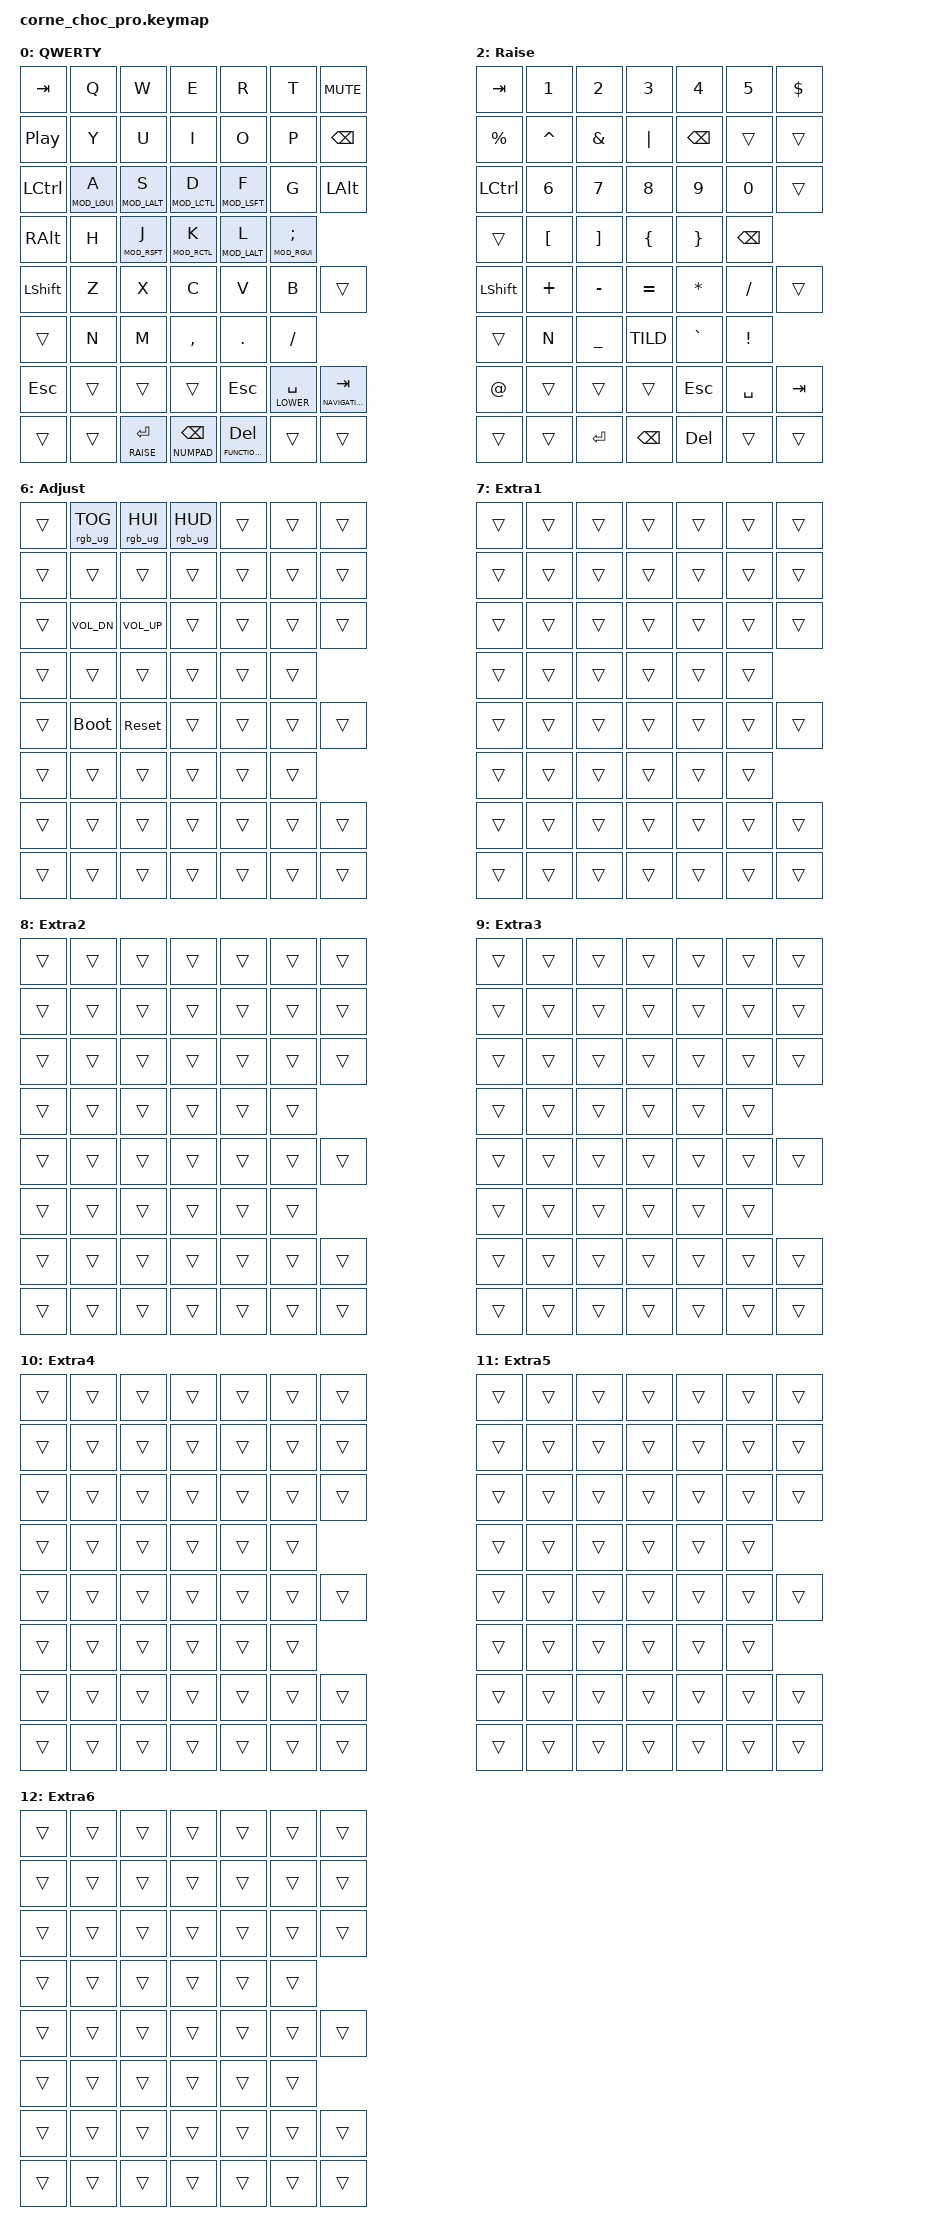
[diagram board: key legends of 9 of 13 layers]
/*
 * Copyright (c) 2020 The ZMK Contributors
 *
 * SPDX-License-Identifier: MIT
 *
 * Corne Choc Pro - 6-column layout (42 keys) with proper &trans for gaps
 * Matrix: 4 rows x 14 columns
 * Physical gaps: Row 2 cols 6-7, Row 3 cols 0-2,6-7,11-13
 */

#include <behaviors.dtsi>
#include <dt-bindings/zmk/keys.h>
#include <dt-bindings/zmk/bt.h>
#include <dt-bindings/zmk/rgb.h>

// Layer definitions - MUST be before any / { block
#define LOWER 1
#define RAISE 2
#define NAVIGATION 3
#define NUMPAD 4
#define FUNCTIONAL 5

/ {
    chosen {
        zmk,physical-layout = &default_layout;
    };
};

/ {
    keymap {
        compatible = "zmk,keymap";

        default_layer {
            display-name = "QWERTY";
            // Row 0: 14 bindings (all columns present)
            // Left: TAB Q W E R T MUTE PP
            // Right: Y U I O P BSPC
            bindings = <
                &kp TAB &kp Q &kp W &kp E &kp R &kp T &kp C_MUTE
                &kp C_PP &kp Y &kp U &kp I &kp O &kp P &kp BSPC
                // Row 1: 14 bindings (all columns present)
                // Left: LCTRL GUI+A ALT+S CTL+D SFT+F G LALT
                // Right: RALT H SFT+J CTL+K ALT+L GUI+; "
                &kp LCTRL &mt MOD_LGUI A &mt MOD_LALT S &mt MOD_LCTL D &mt MOD_LSFT F &kp G
                &kp LALT &kp RALT &kp H &mt MOD_RSFT J &mt MOD_RCTL K &mt MOD_LALT L &mt MOD_RGUI SEMI
                // Row 2: 14 bindings (gap at columns 6-7)
                // Left: LSHFT Z X C V B
                // Gap at positions 6-7
                // Right: N M , . / ESC
                &kp LSHFT &kp Z &kp X &kp C &kp V &kp B &trans &trans
                &kp N &kp M &kp COMMA &kp DOT &kp FSLH &kp ESC
                // Row 3: 14 bindings (gaps at 0-2, 6-7, 11-13)
                // Left thumb: ESC (pos 3), LT(LOWER, SPACE) (pos 4), LT(NAV, TAB) (pos 5)
                // Right thumb: LT(RAISE, RET) (pos 8), LT(NUMPAD, BSPC) (pos 9), LT(FUNC, DEL) (pos 10)
                &trans &trans &trans &kp ESC &lt LOWER SPACE &lt NAVIGATION TAB
                &trans &trans &lt RAISE RET &lt NUMPAD BSPC &lt FUNCTIONAL DEL &trans &trans
            >;
        };

        lower_layer {
            display-name = "Lower";
            bindings = <
                &kp TAB &kp EXCL &kp AT &kp HASH &kp DLLR &kp PRCNT &kp LCTRL
                &kp RCTRL &kp CARET &kp SQT &kp DQT &kp BSLH &kp MINUS &kp EQUAL
                &kp LCTL &kp AMPS &kp ASTRK &kp UNDER &kp PIPE &kp TILD &trans
                &trans &kp GRAVE &kp LEFT &kp DOWN &kp UP &kp RIGHT &kp BSPC
                &kp LSHFT &kp LBRC &kp RBRC &kp LPRN &kp RPRN &kp GRAVE &trans
                &trans &kp N &kp HOME &kp PGUP &kp PGDN &kp END &kp DEL
                &trans &trans &trans &kp ESC &lt LOWER SPACE &kp TAB
                &trans &trans &kp RET &kp BSPC &kp DEL &trans &trans
            >;
        };

        raise_layer {
            display-name = "Raise";
            bindings = <
                &kp TAB &kp N1 &kp N2 &kp N3 &kp N4 &kp N5 &kp DLLR
                &kp PRCNT &kp CARET &kp AMPS &kp PIPE &kp BSPC &trans &trans
                &kp LCTL &kp N6 &kp N7 &kp N8 &kp N9 &kp N0 &trans
                &trans &kp LBKT &kp RBKT &kp LBRC &kp RBRC &kp BSPC
                &kp LSHFT &kp PLUS &kp MINUS &kp EQUAL &kp ASTRK &kp SLASH &trans
                &trans &kp N &kp UNDER &kp TILD &kp GRAVE &kp EXCL &kp AT
                &trans &trans &trans &kp ESC &kp SPACE &kp TAB
                &trans &trans &kp RET &kp BSPC &kp DEL &trans &trans
            >;
        };

        navigation_layer {
            display-name = "Navigation";
            bindings = <
                &kp TAB &kp PSCRN &kp SLCK &kp PAUS &kp INS &trans &trans
                &trans &trans &trans &trans &trans &trans &kp BSPC
                &kp LCTL &kp HOME &kp PGUP &kp PGDN &kp END &trans &trans
                &trans &kp LEFT &kp DOWN &kp UP &kp RIGHT &kp BSPC
                &kp LSHFT &kp LEFT &kp UP &kp DOWN &kp RIGHT &trans &trans
                &kp N &trans &trans &trans &trans &trans
                &trans &trans &trans &kp ESC &kp SPACE &kp TAB
                &trans &trans &kp RET &kp BSPC &kp DEL &trans &trans
            >;
        };

        numpad_layer {
            display-name = "Numpad";
            bindings = <
                &kp TAB &kp N7 &kp N8 &kp N9 &kp PLUS &kp ASTRK &trans
                &trans &trans &trans &trans &trans &kp BSPC
                &kp LCTL &kp N4 &kp N5 &kp N6 &kp MINUS &kp EQUAL &trans
                &trans &trans &trans &trans &trans &kp BSPC
                &kp LSHFT &kp N1 &kp N2 &kp N3 &kp SLASH &kp COMMA &trans
                &kp N &trans &trans &trans &trans &trans
                &trans &trans &trans &kp ESC &kp SPACE &kp TAB
                &trans &trans &kp RET &kp BSPC &kp DEL &trans &trans
            >;
        };

        functional_layer {
            display-name = "Function";
            bindings = <
                &kp TAB &kp F7 &kp F8 &kp F9 &kp F10 &kp F11 &kp F12
                &trans &trans &trans &trans &trans &trans &kp BSPC
                &kp LCTL &kp F4 &kp F5 &kp F6 &kp F12 &kp ESC &trans
                &trans &kp F4 &kp F5 &kp F6 &kp F12 &kp BSPC
                &kp LSHFT &kp F1 &kp F2 &kp F3 &kp DEL &kp INS &trans
                &kp N &kp F1 &kp F2 &kp F3 &kp DEL &kp INS
                &trans &trans &trans &kp ESC &kp SPACE &kp TAB
                &trans &trans &kp RET &kp BSPC &kp DEL &trans &trans
            >;
        };

        adjust_layer {
            display-name = "Adjust";
            bindings = <
                &trans &rgb_ug RGB_TOG &rgb_ug RGB_HUI &rgb_ug RGB_HUD &trans &trans &trans
                &trans &trans &trans &trans &trans &trans &trans
                &trans &kp C_VOL_DN &kp C_VOL_UP &trans &trans &trans &trans
                &trans &trans &trans &trans &trans &trans
                &trans &bootloader &sys_reset &trans &trans &trans &trans
                &trans &trans &trans &trans &trans &trans
                &trans &trans &trans &trans &trans &trans &trans
                &trans &trans &trans &trans &trans &trans &trans
            >;
        };

        extra_layer_1 {
            display-name = "Extra1";
            bindings = <
                &trans &trans &trans &trans &trans &trans &trans
                &trans &trans &trans &trans &trans &trans &trans
                &trans &trans &trans &trans &trans &trans &trans
                &trans &trans &trans &trans &trans &trans
                &trans &trans &trans &trans &trans &trans &trans
                &trans &trans &trans &trans &trans &trans
                &trans &trans &trans &trans &trans &trans &trans
                &trans &trans &trans &trans &trans &trans &trans
            >;
        };

        extra_layer_2 {
            display-name = "Extra2";
            bindings = <
                &trans &trans &trans &trans &trans &trans &trans
                &trans &trans &trans &trans &trans &trans &trans
                &trans &trans &trans &trans &trans &trans &trans
                &trans &trans &trans &trans &trans &trans
                &trans &trans &trans &trans &trans &trans &trans
                &trans &trans &trans &trans &trans &trans
                &trans &trans &trans &trans &trans &trans &trans
                &trans &trans &trans &trans &trans &trans &trans
            >;
        };

        extra_layer_3 {
            display-name = "Extra3";
            bindings = <
                &trans &trans &trans &trans &trans &trans &trans
                &trans &trans &trans &trans &trans &trans &trans
                &trans &trans &trans &trans &trans &trans &trans
                &trans &trans &trans &trans &trans &trans
                &trans &trans &trans &trans &trans &trans &trans
                &trans &trans &trans &trans &trans &trans
                &trans &trans &trans &trans &trans &trans &trans
                &trans &trans &trans &trans &trans &trans &trans
            >;
        };

        extra_layer_4 {
            display-name = "Extra4";
            bindings = <
                &trans &trans &trans &trans &trans &trans &trans
                &trans &trans &trans &trans &trans &trans &trans
                &trans &trans &trans &trans &trans &trans &trans
                &trans &trans &trans &trans &trans &trans
                &trans &trans &trans &trans &trans &trans &trans
                &trans &trans &trans &trans &trans &trans
                &trans &trans &trans &trans &trans &trans &trans
                &trans &trans &trans &trans &trans &trans &trans
            >;
        };

        extra_layer_5 {
            display-name = "Extra5";
            bindings = <
                &trans &trans &trans &trans &trans &trans &trans
                &trans &trans &trans &trans &trans &trans &trans
                &trans &trans &trans &trans &trans &trans &trans
                &trans &trans &trans &trans &trans &trans
                &trans &trans &trans &trans &trans &trans &trans
                &trans &trans &trans &trans &trans &trans
                &trans &trans &trans &trans &trans &trans &trans
                &trans &trans &trans &trans &trans &trans &trans
            >;
        };

        extra_layer_6 {
            display-name = "Extra6";
            bindings = <
                &trans &trans &trans &trans &trans &trans &trans
                &trans &trans &trans &trans &trans &trans &trans
                &trans &trans &trans &trans &trans &trans &trans
                &trans &trans &trans &trans &trans &trans
                &trans &trans &trans &trans &trans &trans &trans
                &trans &trans &trans &trans &trans &trans
                &trans &trans &trans &trans &trans &trans &trans
                &trans &trans &trans &trans &trans &trans &trans
            >;
        };
    };
};
